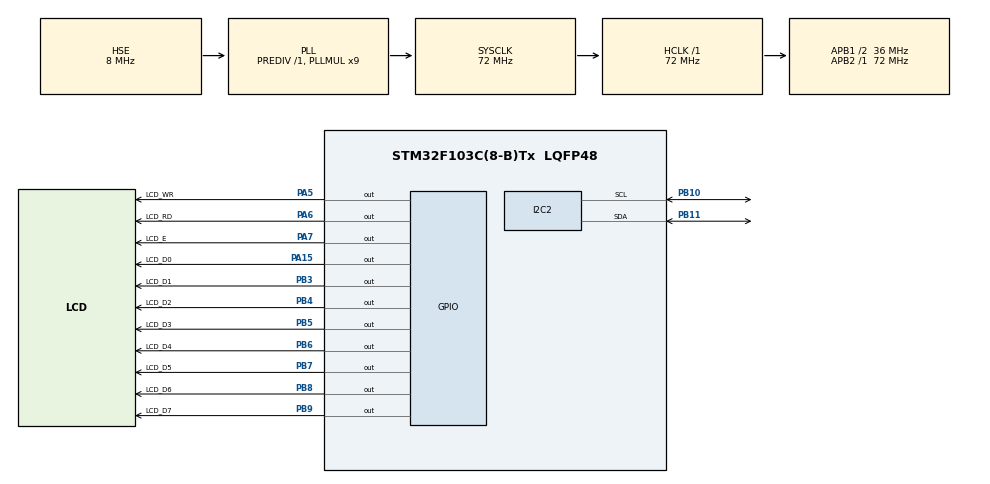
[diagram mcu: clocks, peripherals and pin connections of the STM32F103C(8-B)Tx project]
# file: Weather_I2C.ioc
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Mcu.Family=STM32F1
Mcu.Name=STM32F103C(8-B)Tx
Mcu.Package=LQFP48
NVIC.PriorityGroup=NVIC_PRIORITYGROUP_4
PA15.GPIO_Label=LCD_D0
PA15.Signal=GPIO_Output
PA5.GPIO_Label=LCD_WR
PA5.Signal=GPIO_Output
PA6.GPIO_Label=LCD_RD
PA6.Signal=GPIO_Output
PA7.GPIO_Label=LCD_E
PA7.Signal=GPIO_Output
PB10.Mode=I2C
PB10.Signal=I2C2_SCL
PB11.Mode=I2C
PB11.Signal=I2C2_SDA
PB3.GPIO_Label=LCD_D1
PB3.Signal=GPIO_Output
PB4.GPIO_Label=LCD_D2
PB4.Signal=GPIO_Output
PB5.GPIO_Label=LCD_D3
PB5.Signal=GPIO_Output
PB6.GPIO_Label=LCD_D4
PB6.Signal=GPIO_Output
PB7.GPIO_Label=LCD_D5
PB7.Signal=GPIO_Output
PB8.GPIO_Label=LCD_D6
PB8.Signal=GPIO_Output
PB9.GPIO_Label=LCD_D7
PB9.Signal=GPIO_Output
PD0-OSC_IN.Mode=HSE-External-Oscillator
PD0-OSC_IN.Signal=RCC_OSC_IN
PD1-OSC_OUT.Mode=HSE-External-Oscillator
PD1-OSC_OUT.Signal=RCC_OSC_OUT
ProjectManager.HeapSize=0x200
ProjectManager.StackSize=0x400
ProjectManager.TargetToolchain=STM32CubeIDE
RCC.AHBFreq_Value=72000000
RCC.APB1CLKDivider=RCC_HCLK_DIV2
RCC.APB1Freq_Value=36000000
RCC.APB1TimFreq_Value=72000000
RCC.APB2Freq_Value=72000000
RCC.APB2TimFreq_Value=72000000
RCC.HCLKFreq_Value=72000000
RCC.PLLMUL=RCC_PLL_MUL9
RCC.PLLSourceVirtual=RCC_PLLSOURCE_HSE
RCC.SYSCLKFreq_VALUE=72000000
RCC.SYSCLKSource=RCC_SYSCLKSOURCE_PLLCLK
RCC.USBFreq_Value=72000000
VP_SYS_VS_ND.Mode=No_Debug
board=custom

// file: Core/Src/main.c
/* USER CODE BEGIN Header */
/**
  ******************************************************************************
  * @file           : main.c
  * @brief          : Main program body
  ******************************************************************************
  * @attention
  *
  * <h2><center>&copy; Copyright (c) 2020 STMicroelectronics.
  * All rights reserved.</center></h2>
  *
  * This software component is licensed by ST under BSD 3-Clause license,
  * the "License"; You may not use this file except in compliance with the
  * License. You may obtain a copy of the License at:
  *                        opensource.org/licenses/BSD-3-Clause
  *
  ******************************************************************************
  */
/* USER CODE END Header */
#include "main.h"

I2C_HandleTypeDef hi2c2;

void SystemClock_Config(void);
static void MX_GPIO_Init(void);
static void MX_I2C2_Init(void);

int main(void)
{

  /* MCU Configuration--------------------------------------------------------*/

  /* Reset of all peripherals, Initializes the Flash interface and the Systick. */
  HAL_Init();

  /* Configure the system clock */
  SystemClock_Config();

  /* Initialize all configured peripherals */
  MX_GPIO_Init();
  MX_I2C2_Init();
  /* USER CODE BEGIN 2 */

  BMP280_SETTINGS bmp280={
  		.powermode=POWER_MODE_NORMAL,
  		.oversampling_temp=OVERSAMPLING_x1,
  		.oversampling_press=OVERSAMPLING_x4,
  		.standy_time=STANDBY_TIME_005,
  		.filter_coefficient=FILTER_MODE_4,
  		.spi3w=SPI3W_DISABLE,
  };

  /* USER CODE END 2 */

  /* Infinite loop */
  while (1)
  {

	  lcd_init();
	  BMP280_init(bmp280);

	  getDig_T();
	  int32_t temp=bmp280_compensate_T_int32(BMP280_temp_read());
	  lcd_temp_show(temp);

	  lcd_writeCom(0x80|0x40);

	  getDig_P();
	  uint32_t press=bmp280_compensate_P_int32(BMP280_press_read());
	  lcd_press_show(press);
	  HAL_Delay(1000);
  }
}

void SystemClock_Config(void)
{
  RCC_OscInitTypeDef RCC_OscInitStruct = {0};
  RCC_ClkInitTypeDef RCC_ClkInitStruct = {0};

  /** Initializes the RCC Oscillators according to the specified parameters
  * in the RCC_OscInitTypeDef structure.
  */
  RCC_OscInitStruct.OscillatorType = RCC_OSCILLATORTYPE_HSE;
  RCC_OscInitStruct.HSEState = RCC_HSE_ON;
  RCC_OscInitStruct.HSEPredivValue = RCC_HSE_PREDIV_DIV1;
  RCC_OscInitStruct.HSIState = RCC_HSI_ON;
  RCC_OscInitStruct.PLL.PLLState = RCC_PLL_ON;
  RCC_OscInitStruct.PLL.PLLSource = RCC_PLLSOURCE_HSE;
  RCC_OscInitStruct.PLL.PLLMUL = RCC_PLL_MUL9;
  if (HAL_RCC_OscConfig(&RCC_OscInitStruct) != HAL_OK)
  {
    Error_Handler();
  }
  /** Initializes the CPU, AHB and APB buses clocks
  */
  RCC_ClkInitStruct.ClockType = RCC_CLOCKTYPE_HCLK|RCC_CLOCKTYPE_SYSCLK
                              |RCC_CLOCKTYPE_PCLK1|RCC_CLOCKTYPE_PCLK2;
  RCC_ClkInitStruct.SYSCLKSource = RCC_SYSCLKSOURCE_PLLCLK;
  RCC_ClkInitStruct.AHBCLKDivider = RCC_SYSCLK_DIV1;
  RCC_ClkInitStruct.APB1CLKDivider = RCC_HCLK_DIV2;
  RCC_ClkInitStruct.APB2CLKDivider = RCC_HCLK_DIV1;

  if (HAL_RCC_ClockConfig(&RCC_ClkInitStruct, FLASH_LATENCY_2) != HAL_OK)
  {
    Error_Handler();
  }
}

static void MX_I2C2_Init(void)
{

  hi2c2.Instance = I2C2;
  hi2c2.Init.ClockSpeed = 100000;
  hi2c2.Init.DutyCycle = I2C_DUTYCYCLE_2;
  hi2c2.Init.OwnAddress1 = 0;
  hi2c2.Init.AddressingMode = I2C_ADDRESSINGMODE_7BIT;
  hi2c2.Init.DualAddressMode = I2C_DUALADDRESS_DISABLE;
  hi2c2.Init.OwnAddress2 = 0;
  hi2c2.Init.GeneralCallMode = I2C_GENERALCALL_DISABLE;
  hi2c2.Init.NoStretchMode = I2C_NOSTRETCH_DISABLE;
  if (HAL_I2C_Init(&hi2c2) != HAL_OK)
  {
    Error_Handler();
  }

}

static void MX_GPIO_Init(void)
{
  GPIO_InitTypeDef GPIO_InitStruct = {0};

  /* GPIO Ports Clock Enable */
  __HAL_RCC_GPIOD_CLK_ENABLE();
  __HAL_RCC_GPIOA_CLK_ENABLE();
  __HAL_RCC_GPIOB_CLK_ENABLE();

  /*Configure GPIO pin Output Level */
  HAL_GPIO_WritePin(GPIOA, LCD_WR_Pin|LCD_RD_Pin|LCD_E_Pin|LCD_D0_Pin, GPIO_PIN_RESET);

  /*Configure GPIO pin Output Level */
  HAL_GPIO_WritePin(GPIOB, LCD_D1_Pin|LCD_D2_Pin|LCD_D3_Pin|LCD_D4_Pin
                          |LCD_D5_Pin|LCD_D6_Pin|LCD_D7_Pin, GPIO_PIN_RESET);

  /*Configure GPIO pins : LCD_WR_Pin LCD_RD_Pin LCD_E_Pin LCD_D0_Pin */
  GPIO_InitStruct.Pin = LCD_WR_Pin|LCD_RD_Pin|LCD_E_Pin|LCD_D0_Pin;
  GPIO_InitStruct.Mode = GPIO_MODE_OUTPUT_PP;
  GPIO_InitStruct.Pull = GPIO_NOPULL;
  GPIO_InitStruct.Speed = GPIO_SPEED_FREQ_LOW;
  HAL_GPIO_Init(GPIOA, &GPIO_InitStruct);

  /*Configure GPIO pins : LCD_D1_Pin LCD_D2_Pin LCD_D3_Pin LCD_D4_Pin
                           LCD_D5_Pin LCD_D6_Pin LCD_D7_Pin */
  GPIO_InitStruct.Pin = LCD_D1_Pin|LCD_D2_Pin|LCD_D3_Pin|LCD_D4_Pin
                          |LCD_D5_Pin|LCD_D6_Pin|LCD_D7_Pin;
  GPIO_InitStruct.Mode = GPIO_MODE_OUTPUT_PP;
  GPIO_InitStruct.Pull = GPIO_NOPULL;
  GPIO_InitStruct.Speed = GPIO_SPEED_FREQ_LOW;
  HAL_GPIO_Init(GPIOB, &GPIO_InitStruct);

}

void Error_Handler(void)
{
}

/************************ (C) COPYRIGHT STMicroelectronics *****END OF FILE****/
